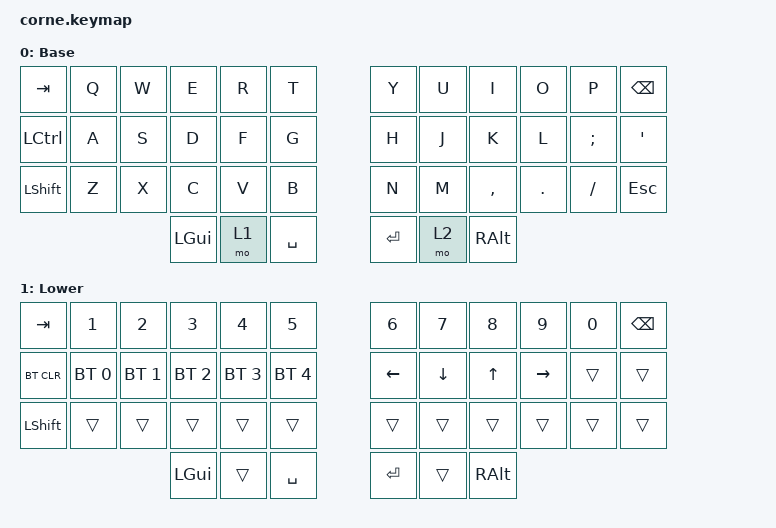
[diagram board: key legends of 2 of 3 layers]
/*
 * Copyright (c) 2020 The ZMK Contributors
 *
 * SPDX-License-Identifier: MIT
 */

#include <behaviors.dtsi>
#include <dt-bindings/zmk/keys.h>
#include <dt-bindings/zmk/bt.h>
#include <dt-bindings/zmk/outputs.h>
#include <dt-bindings/zmk/rgb.h>
#include <dt-bindings/zmk/backlight.h>
#include <dt-bindings/zmk/ext_power.h>


/*
 * Temporarily here because nice nano v2 spi is not defined on ZMk Yet
 * Source: https://github.com/zmkfirmware/zmk/blob/main/app/boards/shields/reviung41/boards/nice_nano.overlay
 * GitHub Issue: https://github.com/zmkfirmware/zmk/issues/885
 */
 
#include <dt-bindings/led/led.h>
&spi1 {
	compatible = "nordic,nrf-spim";
	status = "okay";
	mosi-pin = <6>;
	// Unused pins, needed for SPI definition, but not used by the ws2812 driver itself.
	sck-pin = <5>;
	miso-pin = <7>;

	led_strip: ws2812@0 {
		compatible = "worldsemi,ws2812-spi";
		label = "WS2812";

		/* SPI */
		reg = <0>; /* ignored, but necessary for SPI bindings */
		spi-max-frequency = <4000000>;

		/* WS2812 */
		chain-length = <10>; /* arbitrary; change at will */
		spi-one-frame = <0x70>;
		spi-zero-frame = <0x40>;
		color-mapping = <LED_COLOR_ID_GREEN LED_COLOR_ID_RED LED_COLOR_ID_BLUE>;
	};
};

//&pwm0 {
//    status = "okay";
//    ch0-pin = <45>;
//    /* ch0-inverted; */
//};

&pwm0 {
    status = "okay";
    ch0-pin = <45>;
    /* ch0-inverted; */
};

/ {
    backlight: gpioleds {
        compatible = "gpio-leds";
        label = "Backlight LEDs";
        gpio_led_0 {
            gpios = <&pro_micro 20 GPIO_ACTIVE_LOW>;
            label = "Backlight LED 0";
        };
        gpio_led_1 {
            gpios = <&pro_micro 20 GPIO_ACTIVE_LOW>;
            label = "Backlight LED 0";
        };
        gpio_led_2 {
            gpios = <&pro_micro 20 GPIO_ACTIVE_LOW>;
            label = "Backlight LED 0";
        };
    };

     leds {
             compatible = "gpio-leds";
             led_0 {
                     gpios = <&gpio0 1 GPIO_ACTIVE_LOW>;
             };
             led_1 {
                     gpios = <&gpio0 2 GPIO_ACTIVE_HIGH>;
             };
             led_2 {
                     gpios = <&gpio1 15 (GPIO_PULL_UP | GPIO_ACTIVE_LOW)>;
             };
     };

	chosen {
		zmk,underglow = &led_strip;
		zmk,backlight = &backlight;
	};

        keymap {
                compatible = "zmk,keymap";

                default_layer {
                    label = "Base";
// -----------------------------------------------------------------------------------------
// |  TAB |  Q  |  W  |  E  |  R  |  T  |   |  Y  |  U   |  I  |  O  |  P  | BKSP |
// | CTRL |  A  |  S  |  D  |  F  |  G  |   |  H  |  J   |  K  |  L  |  ;  |  '   |
// | SHFT |  Z  |  X  |  C  |  V  |  B  |   |  N  |  M   |  ,  |  .  |  /  | ESC  |
//                    | GUI | LWR | SPC |   | ENT | RSE  | ALT |
                        bindings = <
   &kp TAB   &kp Q &kp W &kp E &kp R &kp T   &kp Y &kp U  &kp I     &kp O   &kp P    &kp BSPC
   &kp LCTRL &kp A &kp S &kp D &kp F &kp G   &kp H &kp J  &kp K     &kp L   &kp SEMI &kp SQT
   &kp LSHFT &kp Z &kp X &kp C &kp V &kp B   &kp N &kp M  &kp COMMA &kp DOT &kp FSLH &kp ESC
                  &kp LGUI &mo 1 &kp SPACE   &kp RET &mo 2 &kp RALT
                        >;
                };
                lower_layer {
                    label = "Lower";
// -----------------------------------------------------------------------------------------
// |  TAB |  1  |  2  |  3  |  4  |  5  |   |  6  |  7  |  8  |  9  |  0  | BKSP |
// | BTCLR| BT1 | BT2 | BT3 | BT4 | BT5 |   | LFT | DWN |  UP | RGT |     |      |
// | SHFT |     |     |     |     |     |   |     |     |     |     |     |      |
//                    | GUI |     | SPC |   | ENT |     | ALT |
                        bindings = <
   &kp TAB    &kp N1       &kp N2       &kp N3       &kp N4       &kp N5         &kp N6   &kp N7   &kp N8 &kp N9    &kp N0 &kp BSPC
   &bt BT_CLR &bt BT_SEL 0 &bt BT_SEL 1 &bt BT_SEL 2 &bt BT_SEL 3 &bt BT_SEL 4   &kp LEFT &kp DOWN &kp UP &kp RIGHT &trans &trans
   &kp LSHFT  &trans       &trans       &trans       &trans       &trans         &trans   &trans   &trans &trans    &trans &trans
                          	        &kp LGUI     &trans       &kp SPACE      &kp RET  &trans   &kp RALT
                        >;
                };

                raise_layer {
                    label = "Raised";
// -----------------------------------------------------------------------------------------
// |  TAB |  !  |  @  |  #  |  $  |  %  |   |  ^  |  &  |  *  |  (  |  )  | BKSP |
// | CTRL |     |     |     |     |     |   |  -  |  =  |  [  |  ]  |  \  |  `   |
// | SHFT |     |     |     |     |     |   |  _  |  +  |  {  |  }  | "|" |  ~   |
//                    | GUI |     | SPC |   | ENT |     | ALT | BLT | CYC
                        bindings = <
   &kp  TAB  &kp EXCL &kp AT &kp HASH &kp DLLR &kp PRCNT   &kp CARET &kp AMPS  &kp KP_MULTIPLY &kp LPAR &kp RPAR &kp BSPC
   &kp LCTRL &trans   &trans &trans   &trans   &trans      &kp MINUS &kp EQUAL &kp LBKT        &kp RBKT &kp BSLH &kp GRAVE
   &kp LSHFT &trans   &trans &trans   &trans   &trans      &kp UNDER &kp PLUS  &kp LBRC        &kp RBRC &kp PIPE &kp TILDE
                    	     &kp LGUI &trans   &kp SPACE   &kp RET   &trans    &kp RALT        &bl BL_TOG &bl BL_CYCLE
                        >;
                };
        };
};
